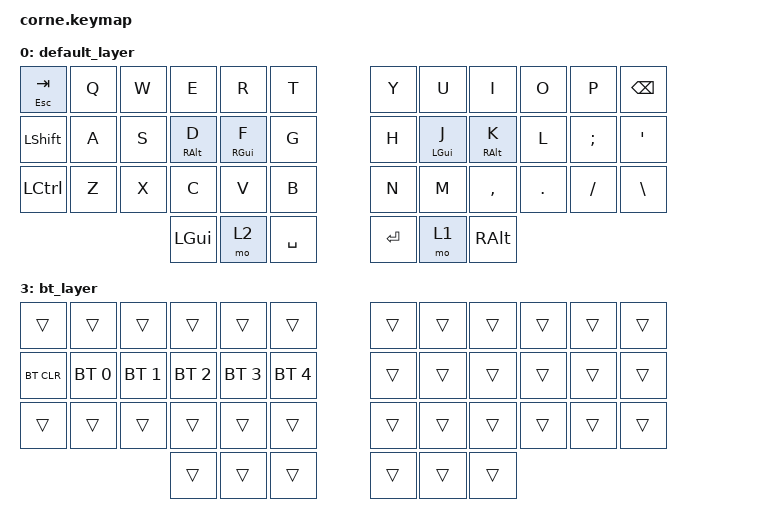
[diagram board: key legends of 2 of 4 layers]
/*
 * Copyright (c) 2020 The ZMK Contributors
 *
 * SPDX-License-Identifier: MIT
 */

#include <behaviors.dtsi>
#include <dt-bindings/zmk/bt.h>
#include <dt-bindings/zmk/keys.h>   

/ {
    behaviors {
        mt: mod_tap {
            compatible = "zmk,behavior-hold-tap";
            #binding-cells = <2>;
            flavor = "balanced";
            tapping-term-ms = <350>;
            quick-tap-ms = <200>;
            require-prior-idle-ms = <125>;
            bindings = <&kp>, <&kp>;
        };
    };

    combos {
        compatible = "zmk,combos";
        l3 {
            bindings = <&mo 3>;
            key-positions = <37 40>;
        };
    };

    keymap {
        compatible = "zmk,keymap";

        default_layer {
            // -----------------------------------------------------------------------------------------
            // |  TAB |  Q  |  W  |  E  |  R  |  T  |   |  Y  |  U   |  I  |  O  |  P  | BSPC |
            // | CTRL |  A  |  S  |  D  |  F  |  G  |   |  H  |  J   |  K  |  L  |  ;  |  '   |
            // | SHFT |  Z  |  X  |  C  |  V  |  B  |   |  N  |  M   |  ,  |  .  |  /  | ESC  |
            //                    | GUI | LWR | SPC |   | ENT | RSE  | ALT |

            bindings = <
&mt ESCAPE TAB  &kp Q  &kp W  &kp E            &kp R            &kp T        &kp Y    &kp U           &kp I            &kp O    &kp P     &kp BSPC
&kp LEFT_SHIFT  &kp A  &kp S  &mt RIGHT_ALT D  &mt RIGHT_GUI F  &kp G        &kp H    &mt LEFT_GUI J  &mt RIGHT_ALT K  &kp L    &kp SEMI  &kp SQT
&kp LCTRL       &kp Z  &kp X  &kp C            &kp V            &kp B        &kp N    &kp M           &kp COMMA        &kp DOT  &kp FSLH  &kp BACKSLASH
                              &kp LGUI         &mo 2            &kp SPACE    &kp RET  &mo 1           &kp RALT
            >;
        };

        lower_layer {
            // -----------------------------------------------------------------------------------------
            // |  TAB |  1  |  2  |  3  |  4  |  5  |   |  6  |  7  |  8  |  9  |  0  | BSPC |
            // | BTCLR| BT1 | BT2 | BT3 | BT4 | BT5 |   | LFT | DWN |  UP | RGT |     |      |
            // | SHFT |     |     |     |     |     |   |     |     |     |     |     |      |
            //                    | GUI |     | SPC |   | ENT |     | ALT |

            bindings = <
&kp TAB    &kp N1          &kp N2        &kp N3           &kp N4      &kp N5        &kp N6         &kp N7    &kp N8    &kp N9        &kp N0     &kp BSPC
&trans     &trans          &trans        &trans           &trans      &trans        &kp PAGE_DOWN  &kp LEFT  &kp DOWN  &kp UP_ARROW  &kp RIGHT  &kp PAGE_UP
&kp LSHFT  &kp C_PREVIOUS  &kp C_VOL_DN  &kp C_VOLUME_UP  &kp C_NEXT  &kp C_MUTE    &trans         &kp HOME  &trans    &trans        &kp END    &trans
                                         &kp LGUI         &trans      &kp SPACE     &kp RET        &trans    &kp RALT
&kp TAB    &kp N1          &kp N2        &kp N3           &kp N4      &kp N5        &kp N6         &kp N7    &kp N8    &kp N9        &kp N0     &kp BSPC
&trans     &trans          &trans        &trans           &trans      &trans        &kp PAGE_DOWN  &kp LEFT  &kp DOWN  &kp UP_ARROW  &kp RIGHT  &kp PAGE_UP
&kp LSHFT  &kp C_PREVIOUS  &kp C_VOL_DN  &kp C_VOLUME_UP  &kp C_NEXT  &kp C_MUTE    &trans         &kp HOME  &trans    &trans        &kp END    &trans
                                         &kp LGUI         &trans      &kp SPACE     &kp RET        &trans    &kp RALT
            >;
        };

        raise_layer {
            // -----------------------------------------------------------------------------------------
            // |  TAB |  !  |  @  |  #  |  $  |  %  |   |  ^  |  &  |  *  |  (  |  )  | BSPC |
            // | CTRL |     |     |     |     |     |   |  -  |  =  |  [  |  ]  |  \  |  `   |
            // | SHFT |     |     |     |     |     |   |  _  |  +  |  {  |  }  | "|" |  ~   |
            //                    | GUI |     | SPC |   | ENT |     | ALT |

            bindings = <
&kp TILDE  &kp EXCL  &kp AT  &kp HASH  &kp DLLR  &kp PRCNT    &kp CARET  &kp AMPS   &kp ASTRK      &kp LPAR          &kp RPAR           &kp DEL
&kp F1     &kp F2    &kp F3  &kp F4    &kp F5    &kp F6       &kp MINUS  &kp EQUAL  &kp BACKSLASH  &kp LEFT_BRACKET  &kp RIGHT_BRACKET  &kp GRAVE
&kp F7     &kp F8    &kp F9  &kp F10   &kp F11   &kp F12      &kp UNDER  &kp PLUS   &kp PIPE       &kp LEFT_BRACE    &kp RIGHT_BRACE    &kp TILDE
&kp TILDE  &kp EXCL  &kp AT  &kp HASH  &kp DLLR  &kp PRCNT    &kp CARET  &kp AMPS   &kp ASTRK      &kp LPAR          &kp RPAR           &kp DEL
&kp F1     &kp F2    &kp F3  &kp F4    &kp F5    &kp F6       &kp MINUS  &kp EQUAL  &kp BACKSLASH  &kp LEFT_BRACKET  &kp RIGHT_BRACKET  &kp GRAVE
&kp F7     &kp F8    &kp F9  &kp F10   &kp F11   &kp F12      &kp UNDER  &kp PLUS   &kp PIPE       &kp LEFT_BRACE    &kp RIGHT_BRACE    &kp TILDE
                             &kp LGUI  &trans    &kp SPACE    &kp RET    &trans     &kp RALT
            >;
        };

        bt_layer {
            bindings = <
&trans      &trans        &trans        &trans        &trans        &trans          &trans  &trans  &trans  &trans  &trans  &trans
&bt BT_CLR  &bt BT_SEL 0  &bt BT_SEL 1  &bt BT_SEL 2  &bt BT_SEL 3  &bt BT_SEL 4    &trans  &trans  &trans  &trans  &trans  &trans
&trans      &trans        &trans        &trans        &trans        &trans          &trans  &trans  &trans  &trans  &trans  &trans
                                        &trans        &trans        &trans          &trans  &trans  &trans
            >;
        };
    };
};
